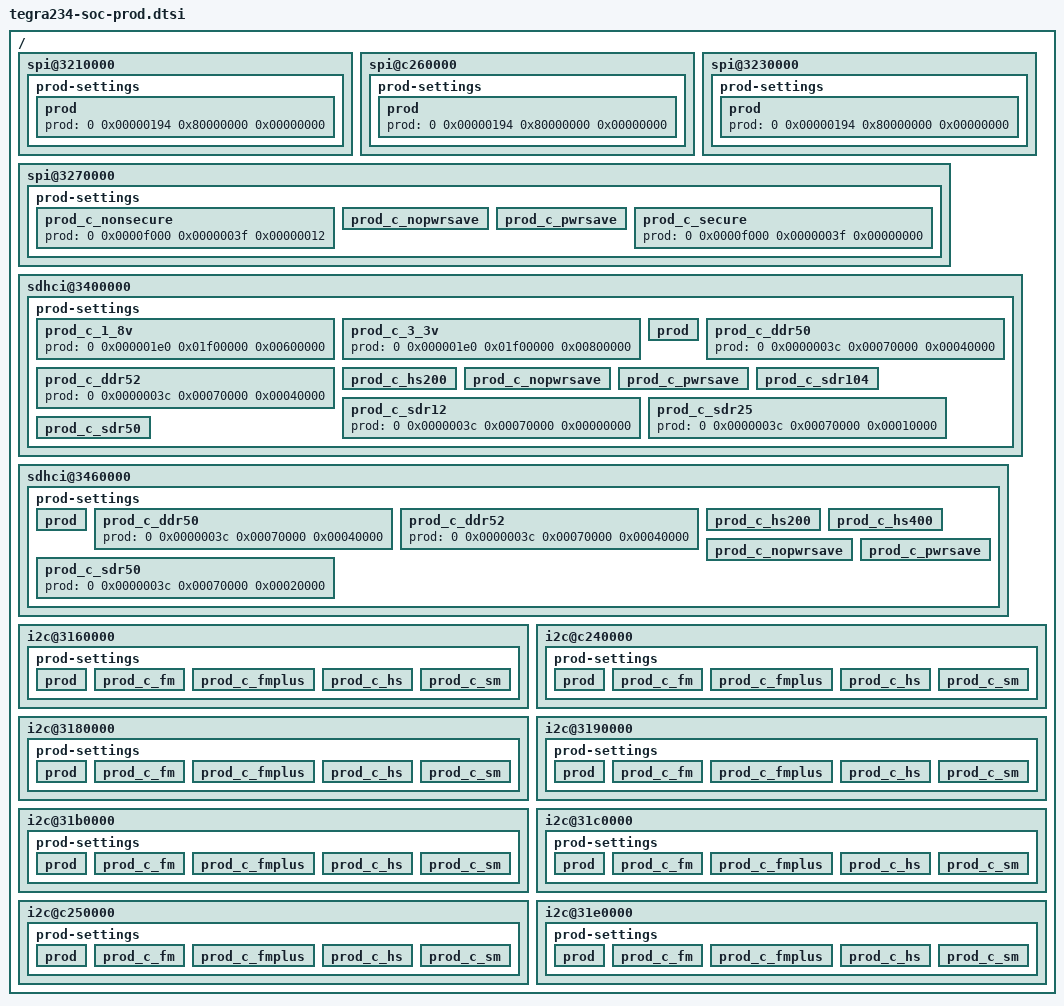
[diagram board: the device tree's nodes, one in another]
/*
 * Copyright (c) 2021, NVIDIA CORPORATION.  All rights reserved.
 *
 * This program is free software; you can redistribute it and/or modify it
 * under the terms and conditions of the GNU General Public License,
 * version 2, as published by the Free Software Foundation.
 *
 * This program is distributed in the hope it will be useful, but WITHOUT
 * ANY WARRANTY; without even the implied warranty of MERCHANTABILITY or
 * FITNESS FOR A PARTICULAR PURPOSE.  See the GNU General Public License for
 * more details.
 *
 * You should have received a copy of the GNU General Public License
 * along with this program.  If not, see <http://www.gnu.org/licenses/>.
 */

/*
* tegra234-soc-prod.dtsi: soc specific Prod configuration.
* Generation date: 2021-08-03 01:08
* PLEASE DO NOT EDIT THIS FILE MANUALLY
* This file is autogenerated using the script gen_prod_dtsi.py V2.3
*/

/ {
	spi@3210000 {
		prod-settings {
			#prod-cells = <4>;
			prod {
				prod = <
					0 0x00000194 0x80000000 0x00000000>;            //SPI_MISC_0
			};
		};
	};

	spi@c260000 {
		prod-settings {
			#prod-cells = <4>;
			prod {
				prod = <
					0 0x00000194 0x80000000 0x00000000>;            //SPI_MISC_0
			};
		};
	};

	spi@3230000 {
		prod-settings {
			#prod-cells = <4>;
			prod {
				prod = <
					0 0x00000194 0x80000000 0x00000000>;            //SPI_MISC_0
			};
		};
	};

	spi@3270000 {
		prod-settings {
			#prod-cells = <4>;
			prod_c_nonsecure {
				prod = <
					0 0x0000f000 0x0000003f 0x00000012>;            //QSPI_SECURE_AXI_CTL_0
			};
			prod_c_nopwrsave {
				prod = <
					0 0x00000194 0x80000000 0x80000000              //QSPI_MISC_0
					0 0x000001ec 0x00000002 0x00000000              //QSPI_QSPI_COMP_CONTROL_0
					0 0x000001fc 0x00000002 0x00000000>;            //QSPI_IO_TRIM_CNTRL_0
			};
			prod_c_pwrsave {
				prod = <
					0 0x00000194 0x80000000 0x00000000              //QSPI_MISC_0
					0 0x000001ec 0x00000002 0x00000002              //QSPI_QSPI_COMP_CONTROL_0
					0 0x000001fc 0x00000002 0x00000002>;            //QSPI_IO_TRIM_CNTRL_0
			};
			prod_c_secure {
				prod = <
					0 0x0000f000 0x0000003f 0x00000000>;            //QSPI_SECURE_AXI_CTL_0
			};
		};
	};

	sdhci@3400000 {
		prod-settings {
			#prod-cells = <4>;
			prod_c_1_8v {
				prod = <
					0 0x000001e0 0x01f00000 0x00600000>;            //SDMMCA_SDMEMCOMPPADCTRL_0
			};
			prod_c_3_3v {
				prod = <
					0 0x000001e0 0x01f00000 0x00800000>;            //SDMMCA_SDMEMCOMPPADCTRL_0
			};
			prod {
				prod = <
					0 0x00000028 0x00000022 0x00000002              //SDMMCA_POWER_CONTROL_HOST_0
					0 0x00000100 0x1fff006a 0x0e080020              //SDMMCA_VENDOR_CLOCK_CNTRL_0
					0 0x00000128 0x42000000 0x00000000              //SDMMCA_VENDOR_MISC_CNTRL2_0
					0 0x000001c0 0x00001fc0 0x00000040              //SDMMCA_VENDOR_TUNING_CNTRL0_0
					0 0x000001e0 0x0001f000 0x00007000              //SDMMCA_SDMEMCOMPPADCTRL_0
					0 0x000001e4 0x20000000 0x20000000>;            //SDMMCA_AUTO_CAL_CONFIG_0
			};
			prod_c_ddr50 {
				prod = <
					0 0x0000003c 0x00070000 0x00040000>;            //SDMMCA_AUTO_CMD12_ERR_STATUS_0
			};
			prod_c_ddr52 {
				prod = <
					0 0x0000003c 0x00070000 0x00040000>;            //SDMMCA_AUTO_CMD12_ERR_STATUS_0
			};
			prod_c_hs200 {
				prod = <
					0 0x0000003c 0x00070000 0x00030000              //SDMMCA_AUTO_CMD12_ERR_STATUS_0
					0 0x000001c0 0x0000e000 0x00004000>;            //SDMMCA_VENDOR_TUNING_CNTRL0_0
			};
			prod_c_nopwrsave {
				prod = <
					0 0x00000100 0x00000001 0x00000001              //SDMMCA_VENDOR_CLOCK_CNTRL_0
					0 0x000001ac 0x00000004 0x00000000>;            //SDMMCA_VENDOR_IO_TRIM_CNTRL_0
			};
			prod_c_pwrsave {
				prod = <
					0 0x00000100 0x00000001 0x00000000              //SDMMCA_VENDOR_CLOCK_CNTRL_0
					0 0x000001ac 0x00000004 0x00000004>;            //SDMMCA_VENDOR_IO_TRIM_CNTRL_0
			};
			prod_c_sdr104 {
				prod = <
					0 0x0000003c 0x00070000 0x00030000              //SDMMCA_AUTO_CMD12_ERR_STATUS_0
					0 0x000001c0 0x0000e000 0x00004000>;            //SDMMCA_VENDOR_TUNING_CNTRL0_0
			};
			prod_c_sdr12 {
				prod = <
					0 0x0000003c 0x00070000 0x00000000>;            //SDMMCA_AUTO_CMD12_ERR_STATUS_0
			};
			prod_c_sdr25 {
				prod = <
					0 0x0000003c 0x00070000 0x00010000>;            //SDMMCA_AUTO_CMD12_ERR_STATUS_0
			};
			prod_c_sdr50 {
				prod = <
					0 0x0000003c 0x00070000 0x00020000              //SDMMCA_AUTO_CMD12_ERR_STATUS_0
					0 0x000001c0 0x0000e000 0x00008000>;            //SDMMCA_VENDOR_TUNING_CNTRL0_0
			};
		};
	};

	sdhci@3460000 {
		prod-settings {
			#prod-cells = <4>;
			prod {
				prod = <
					0 0x00000004 0x00000fff 0x00000200              //SDMMCAB_BLOCK_SIZE_BLOCK_COUNT_0
					0 0x00000028 0x00000020 0x00000020              //SDMMCAB_POWER_CONTROL_HOST_0
					0 0x00000100 0x1fff006a 0x12070020              //SDMMCAB_VENDOR_CLOCK_CNTRL_0
					0 0x00000120 0x0000fffe 0x00000298              //SDMMCAB_VENDOR_MISC_CNTRL_0
					0 0x00000128 0x43000000 0x00000000              //SDMMCAB_VENDOR_MISC_CNTRL2_0
					0 0x000001c0 0x00001fc0 0x00000040              //SDMMCAB_VENDOR_TUNING_CNTRL0_0
					0 0x000001e0 0x01f1f000 0x00a0a000              //SDMMCAB_SDMEMCOMPPADCTRL_0
					0 0x000001e4 0x20000000 0x20000000>;            //SDMMCAB_AUTO_CAL_CONFIG_0
			};
			prod_c_ddr50 {
				prod = <
					0 0x0000003c 0x00070000 0x00040000>;            //SDMMCAB_AUTO_CMD12_ERR_STATUS_0
			};
			prod_c_ddr52 {
				prod = <
					0 0x0000003c 0x00070000 0x00040000>;            //SDMMCAB_AUTO_CMD12_ERR_STATUS_0
			};
			prod_c_hs200 {
				prod = <
					0 0x0000003c 0x00070000 0x00030000              //SDMMCAB_AUTO_CMD12_ERR_STATUS_0
					0 0x000001c0 0x0000e000 0x00004000>;            //SDMMCAB_VENDOR_TUNING_CNTRL0_0
			};
			prod_c_hs400 {
				prod = <
					0 0x0000003c 0x00070000 0x00050000              //SDMMCAB_AUTO_CMD12_ERR_STATUS_0
					0 0x00000100 0x00000008 0x00000008              //SDMMCAB_VENDOR_CLOCK_CNTRL_0
					0 0x0000010c 0x00003f00 0x00002800              //SDMMCAB_VENDOR_CAP_OVERRIDES_0
					0 0x000001c0 0x0000e000 0x00004000>;            //SDMMCAB_VENDOR_TUNING_CNTRL0_0
			};
			prod_c_nopwrsave {
				prod = <
					0 0x00000100 0x00000001 0x00000001              //SDMMCAB_VENDOR_CLOCK_CNTRL_0
					0 0x000001ac 0x00000004 0x00000000>;            //SDMMCAB_VENDOR_IO_TRIM_CNTRL_0
			};
			prod_c_pwrsave {
				prod = <
					0 0x00000100 0x00000001 0x00000000              //SDMMCAB_VENDOR_CLOCK_CNTRL_0
					0 0x000001ac 0x00000004 0x00000004>;            //SDMMCAB_VENDOR_IO_TRIM_CNTRL_0
			};
			prod_c_sdr50 {
				prod = <
					0 0x0000003c 0x00070000 0x00020000>;            //SDMMCAB_AUTO_CMD12_ERR_STATUS_0
			};
		};
	};
	i2c@3160000 {
		prod-settings {
			#prod-cells = <4>;
			prod {
				prod = <
					0 0x0000009c 0x0000ffff 0x00000308              //I2C_I2C_HS_INTERFACE_TIMING_0_0
					0 0x000000d4 0x000000ff 0x00000000              //I2C_I2C_INTERFACE_TIMING_2_0
					0 0x000000d8 0x000000ff 0x00000000              //I2C_I2C_HS_INTERFACE_TIMING_2_0
					0 0x000000dc 0x0000ffff 0x00000001              //I2C_I2C_MSTR_DATA_CAPTURE_TIMING_0
					0 0x000000e0 0x0000ffff 0x00000002>;            //I2C_I2C_SLV_DATA_CAPTURE_TIMING_0
			};
			prod_c_fm {
				prod = <
					0 0x0000006c 0xffff0000 0x00580000              //I2C_I2C_CLK_DIVISOR_REGISTER_0
					0 0x00000094 0x0000ffff 0x00000101              //I2C_I2C_INTERFACE_TIMING_0_0
					0 0x00000098 0xffffffff 0x02020202>;            //I2C_I2C_INTERFACE_TIMING_1_0
			};
			prod_c_fmplus {
				prod = <
					0 0x0000006c 0xffff0000 0x00240000              //I2C_I2C_CLK_DIVISOR_REGISTER_0
					0 0x00000094 0x0000ffff 0x00000101              //I2C_I2C_INTERFACE_TIMING_0_0
					0 0x00000098 0xffffffff 0x02020202>;            //I2C_I2C_INTERFACE_TIMING_1_0
			};
			prod_c_hs {
				prod = <
					0 0x0000006c 0xffffffff 0x00580002              //I2C_I2C_CLK_DIVISOR_REGISTER_0
					0 0x00000094 0x0000ffff 0x00000101              //I2C_I2C_INTERFACE_TIMING_0_0
					0 0x00000098 0xffffffff 0x02020202              //I2C_I2C_INTERFACE_TIMING_1_0
					0 0x000000a0 0x00ffffff 0x00090909>;            //I2C_I2C_HS_INTERFACE_TIMING_1_0
			};
			prod_c_sm {
				prod = <
					0 0x0000006c 0xffff0000 0x004f0000              //I2C_I2C_CLK_DIVISOR_REGISTER_0
					0 0x00000094 0x0000ffff 0x00000708              //I2C_I2C_INTERFACE_TIMING_0_0
					0 0x00000098 0xffffffff 0x08080808>;            //I2C_I2C_INTERFACE_TIMING_1_0
			};
		};
	};

	i2c@c240000 {
		prod-settings {
			#prod-cells = <4>;
			prod {
				prod = <
					0 0x0000009c 0x0000ffff 0x00000308              //I2C_I2C_HS_INTERFACE_TIMING_0_0
					0 0x000000d4 0x000000ff 0x00000000              //I2C_I2C_INTERFACE_TIMING_2_0
					0 0x000000d8 0x000000ff 0x00000000              //I2C_I2C_HS_INTERFACE_TIMING_2_0
					0 0x000000dc 0x0000ffff 0x00000001              //I2C_I2C_MSTR_DATA_CAPTURE_TIMING_0
					0 0x000000e0 0x0000ffff 0x00000002>;            //I2C_I2C_SLV_DATA_CAPTURE_TIMING_0
			};
			prod_c_fm {
				prod = <
					0 0x0000006c 0xffff0000 0x00580000              //I2C_I2C_CLK_DIVISOR_REGISTER_0
					0 0x00000094 0x0000ffff 0x00000101              //I2C_I2C_INTERFACE_TIMING_0_0
					0 0x00000098 0xffffffff 0x02020202>;            //I2C_I2C_INTERFACE_TIMING_1_0
			};
			prod_c_fmplus {
				prod = <
					0 0x0000006c 0xffff0000 0x00240000              //I2C_I2C_CLK_DIVISOR_REGISTER_0
					0 0x00000094 0x0000ffff 0x00000101              //I2C_I2C_INTERFACE_TIMING_0_0
					0 0x00000098 0xffffffff 0x02020202>;            //I2C_I2C_INTERFACE_TIMING_1_0
			};
			prod_c_hs {
				prod = <
					0 0x0000006c 0xffffffff 0x00580002              //I2C_I2C_CLK_DIVISOR_REGISTER_0
					0 0x00000094 0x0000ffff 0x00000101              //I2C_I2C_INTERFACE_TIMING_0_0
					0 0x00000098 0xffffffff 0x02020202              //I2C_I2C_INTERFACE_TIMING_1_0
					0 0x000000a0 0x00ffffff 0x00090909>;            //I2C_I2C_HS_INTERFACE_TIMING_1_0
			};
			prod_c_sm {
				prod = <
					0 0x0000006c 0xffff0000 0x004f0000              //I2C_I2C_CLK_DIVISOR_REGISTER_0
					0 0x00000094 0x0000ffff 0x00000708              //I2C_I2C_INTERFACE_TIMING_0_0
					0 0x00000098 0xffffffff 0x08080808>;            //I2C_I2C_INTERFACE_TIMING_1_0
			};
		};
	};

	i2c@3180000 {
		prod-settings {
			#prod-cells = <4>;
			prod {
				prod = <
					0 0x0000009c 0x0000ffff 0x00000308              //I2C_I2C_HS_INTERFACE_TIMING_0_0
					0 0x000000d4 0x000000ff 0x00000000              //I2C_I2C_INTERFACE_TIMING_2_0
					0 0x000000d8 0x000000ff 0x00000000              //I2C_I2C_HS_INTERFACE_TIMING_2_0
					0 0x000000dc 0x0000ffff 0x00000001              //I2C_I2C_MSTR_DATA_CAPTURE_TIMING_0
					0 0x000000e0 0x0000ffff 0x00000002>;            //I2C_I2C_SLV_DATA_CAPTURE_TIMING_0
			};
			prod_c_fm {
				prod = <
					0 0x0000006c 0xffff0000 0x00580000              //I2C_I2C_CLK_DIVISOR_REGISTER_0
					0 0x00000094 0x0000ffff 0x00000101              //I2C_I2C_INTERFACE_TIMING_0_0
					0 0x00000098 0xffffffff 0x02020202>;            //I2C_I2C_INTERFACE_TIMING_1_0
			};
			prod_c_fmplus {
				prod = <
					0 0x0000006c 0xffff0000 0x00240000              //I2C_I2C_CLK_DIVISOR_REGISTER_0
					0 0x00000094 0x0000ffff 0x00000101              //I2C_I2C_INTERFACE_TIMING_0_0
					0 0x00000098 0xffffffff 0x02020202>;            //I2C_I2C_INTERFACE_TIMING_1_0
			};
			prod_c_hs {
				prod = <
					0 0x0000006c 0xffffffff 0x00580002              //I2C_I2C_CLK_DIVISOR_REGISTER_0
					0 0x00000094 0x0000ffff 0x00000101              //I2C_I2C_INTERFACE_TIMING_0_0
					0 0x00000098 0xffffffff 0x02020202              //I2C_I2C_INTERFACE_TIMING_1_0
					0 0x000000a0 0x00ffffff 0x00090909>;            //I2C_I2C_HS_INTERFACE_TIMING_1_0
			};
			prod_c_sm {
				prod = <
					0 0x0000006c 0xffff0000 0x004f0000              //I2C_I2C_CLK_DIVISOR_REGISTER_0
					0 0x00000094 0x0000ffff 0x00000708              //I2C_I2C_INTERFACE_TIMING_0_0
					0 0x00000098 0xffffffff 0x08080808>;            //I2C_I2C_INTERFACE_TIMING_1_0
			};
		};
	};

	i2c@3190000 {
		prod-settings {
			#prod-cells = <4>;
			prod {
				prod = <
					0 0x0000009c 0x0000ffff 0x00000308              //I2C_I2C_HS_INTERFACE_TIMING_0_0
					0 0x000000d4 0x000000ff 0x00000000              //I2C_I2C_INTERFACE_TIMING_2_0
					0 0x000000d8 0x000000ff 0x00000000              //I2C_I2C_HS_INTERFACE_TIMING_2_0
					0 0x000000dc 0x0000ffff 0x00000001              //I2C_I2C_MSTR_DATA_CAPTURE_TIMING_0
					0 0x000000e0 0x0000ffff 0x00000002>;            //I2C_I2C_SLV_DATA_CAPTURE_TIMING_0
			};
			prod_c_fm {
				prod = <
					0 0x0000006c 0xffff0000 0x00580000              //I2C_I2C_CLK_DIVISOR_REGISTER_0
					0 0x00000094 0x0000ffff 0x00000101              //I2C_I2C_INTERFACE_TIMING_0_0
					0 0x00000098 0xffffffff 0x02020202>;            //I2C_I2C_INTERFACE_TIMING_1_0
			};
			prod_c_fmplus {
				prod = <
					0 0x0000006c 0xffff0000 0x00240000              //I2C_I2C_CLK_DIVISOR_REGISTER_0
					0 0x00000094 0x0000ffff 0x00000101              //I2C_I2C_INTERFACE_TIMING_0_0
					0 0x00000098 0xffffffff 0x02020202>;            //I2C_I2C_INTERFACE_TIMING_1_0
			};
			prod_c_hs {
				prod = <
					0 0x0000006c 0xffffffff 0x00580002              //I2C_I2C_CLK_DIVISOR_REGISTER_0
					0 0x00000094 0x0000ffff 0x00000101              //I2C_I2C_INTERFACE_TIMING_0_0
					0 0x00000098 0xffffffff 0x02020202              //I2C_I2C_INTERFACE_TIMING_1_0
					0 0x000000a0 0x00ffffff 0x00090909>;            //I2C_I2C_HS_INTERFACE_TIMING_1_0
			};
			prod_c_sm {
				prod = <
					0 0x0000006c 0xffff0000 0x004f0000              //I2C_I2C_CLK_DIVISOR_REGISTER_0
					0 0x00000094 0x0000ffff 0x00000708              //I2C_I2C_INTERFACE_TIMING_0_0
					0 0x00000098 0xffffffff 0x08080808>;            //I2C_I2C_INTERFACE_TIMING_1_0
			};
		};
	};
        i2c@31b0000 {
		prod-settings {
			#prod-cells = <4>;
			prod {
				prod = <
					0 0x0000009c 0x0000ffff 0x00000308              //I2C_I2C_HS_INTERFACE_TIMING_0_0
					0 0x000000d4 0x000000ff 0x00000000              //I2C_I2C_INTERFACE_TIMING_2_0
					0 0x000000d8 0x000000ff 0x00000000              //I2C_I2C_HS_INTERFACE_TIMING_2_0
					0 0x000000dc 0x0000ffff 0x00000001              //I2C_I2C_MSTR_DATA_CAPTURE_TIMING_0
					0 0x000000e0 0x0000ffff 0x00000002>;            //I2C_I2C_SLV_DATA_CAPTURE_TIMING_0
			};
			prod_c_fm {
				prod = <
					0 0x0000006c 0xffff0000 0x00580000              //I2C_I2C_CLK_DIVISOR_REGISTER_0
					0 0x00000094 0x0000ffff 0x00000101              //I2C_I2C_INTERFACE_TIMING_0_0
					0 0x00000098 0xffffffff 0x02020202>;            //I2C_I2C_INTERFACE_TIMING_1_0
			};
			prod_c_fmplus {
				prod = <
					0 0x0000006c 0xffff0000 0x00240000              //I2C_I2C_CLK_DIVISOR_REGISTER_0
					0 0x00000094 0x0000ffff 0x00000101              //I2C_I2C_INTERFACE_TIMING_0_0
					0 0x00000098 0xffffffff 0x02020202>;            //I2C_I2C_INTERFACE_TIMING_1_0
			};
			prod_c_hs {
				prod = <
					0 0x0000006c 0xffffffff 0x00580002              //I2C_I2C_CLK_DIVISOR_REGISTER_0
					0 0x00000094 0x0000ffff 0x00000101              //I2C_I2C_INTERFACE_TIMING_0_0
					0 0x00000098 0xffffffff 0x02020202              //I2C_I2C_INTERFACE_TIMING_1_0
					0 0x000000a0 0x00ffffff 0x00090909>;            //I2C_I2C_HS_INTERFACE_TIMING_1_0
			};
			prod_c_sm {
				prod = <
					0 0x0000006c 0xffff0000 0x004f0000              //I2C_I2C_CLK_DIVISOR_REGISTER_0
					0 0x00000094 0x0000ffff 0x00000708              //I2C_I2C_INTERFACE_TIMING_0_0
					0 0x00000098 0xffffffff 0x08080808>;            //I2C_I2C_INTERFACE_TIMING_1_0
			};
		};
	};

	i2c@31c0000 {
		prod-settings {
			#prod-cells = <4>;
			prod {
				prod = <
					0 0x0000009c 0x0000ffff 0x00000308              //I2C_I2C_HS_INTERFACE_TIMING_0_0
					0 0x000000d4 0x000000ff 0x00000000              //I2C_I2C_INTERFACE_TIMING_2_0
					0 0x000000d8 0x000000ff 0x00000000              //I2C_I2C_HS_INTERFACE_TIMING_2_0
					0 0x000000dc 0x0000ffff 0x00000001              //I2C_I2C_MSTR_DATA_CAPTURE_TIMING_0
					0 0x000000e0 0x0000ffff 0x00000002>;            //I2C_I2C_SLV_DATA_CAPTURE_TIMING_0
			};
			prod_c_fm {
				prod = <
					0 0x0000006c 0xffff0000 0x00580000              //I2C_I2C_CLK_DIVISOR_REGISTER_0
					0 0x00000094 0x0000ffff 0x00000101              //I2C_I2C_INTERFACE_TIMING_0_0
					0 0x00000098 0xffffffff 0x02020202>;            //I2C_I2C_INTERFACE_TIMING_1_0
			};
			prod_c_fmplus {
				prod = <
					0 0x0000006c 0xffff0000 0x00240000              //I2C_I2C_CLK_DIVISOR_REGISTER_0
					0 0x00000094 0x0000ffff 0x00000101              //I2C_I2C_INTERFACE_TIMING_0_0
					0 0x00000098 0xffffffff 0x02020202>;            //I2C_I2C_INTERFACE_TIMING_1_0
			};
			prod_c_hs {
				prod = <
					0 0x0000006c 0xffffffff 0x00580002              //I2C_I2C_CLK_DIVISOR_REGISTER_0
					0 0x00000094 0x0000ffff 0x00000101              //I2C_I2C_INTERFACE_TIMING_0_0
					0 0x00000098 0xffffffff 0x02020202              //I2C_I2C_INTERFACE_TIMING_1_0
					0 0x000000a0 0x00ffffff 0x00090909>;            //I2C_I2C_HS_INTERFACE_TIMING_1_0
			};
			prod_c_sm {
				prod = <
					0 0x0000006c 0xffff0000 0x004f0000              //I2C_I2C_CLK_DIVISOR_REGISTER_0
					0 0x00000094 0x0000ffff 0x00000708              //I2C_I2C_INTERFACE_TIMING_0_0
					0 0x00000098 0xffffffff 0x08080808>;            //I2C_I2C_INTERFACE_TIMING_1_0
			};
		};
	};

	i2c@c250000 {
		prod-settings {
			#prod-cells = <4>;
			prod {
				prod = <
					0 0x0000009c 0x0000ffff 0x00000308              //I2C_I2C_HS_INTERFACE_TIMING_0_0
					0 0x000000d4 0x000000ff 0x00000000              //I2C_I2C_INTERFACE_TIMING_2_0
					0 0x000000d8 0x000000ff 0x00000000              //I2C_I2C_HS_INTERFACE_TIMING_2_0
					0 0x000000dc 0x0000ffff 0x00000001              //I2C_I2C_MSTR_DATA_CAPTURE_TIMING_0
					0 0x000000e0 0x0000ffff 0x00000002>;            //I2C_I2C_SLV_DATA_CAPTURE_TIMING_0
			};
			prod_c_fm {
				prod = <
					0 0x0000006c 0xffff0000 0x00580000              //I2C_I2C_CLK_DIVISOR_REGISTER_0
					0 0x00000094 0x0000ffff 0x00000101              //I2C_I2C_INTERFACE_TIMING_0_0
					0 0x00000098 0xffffffff 0x02020202>;            //I2C_I2C_INTERFACE_TIMING_1_0
			};
			prod_c_fmplus {
				prod = <
					0 0x0000006c 0xffff0000 0x00240000              //I2C_I2C_CLK_DIVISOR_REGISTER_0
					0 0x00000094 0x0000ffff 0x00000101              //I2C_I2C_INTERFACE_TIMING_0_0
					0 0x00000098 0xffffffff 0x02020202>;            //I2C_I2C_INTERFACE_TIMING_1_0
			};
			prod_c_hs {
				prod = <
					0 0x0000006c 0xffffffff 0x00580002              //I2C_I2C_CLK_DIVISOR_REGISTER_0
					0 0x00000094 0x0000ffff 0x00000101              //I2C_I2C_INTERFACE_TIMING_0_0
					0 0x00000098 0xffffffff 0x02020202              //I2C_I2C_INTERFACE_TIMING_1_0
					0 0x000000a0 0x00ffffff 0x00090909>;            //I2C_I2C_HS_INTERFACE_TIMING_1_0
			};
			prod_c_sm {
				prod = <
					0 0x0000006c 0xffff0000 0x004f0000              //I2C_I2C_CLK_DIVISOR_REGISTER_0
					0 0x00000094 0x0000ffff 0x00000708              //I2C_I2C_INTERFACE_TIMING_0_0
					0 0x00000098 0xffffffff 0x08080808>;            //I2C_I2C_INTERFACE_TIMING_1_0
			};
		};
	};

	i2c@31e0000 {
		prod-settings {
			#prod-cells = <4>;
			prod {
				prod = <
					0 0x0000009c 0x0000ffff 0x00000308              //I2C_I2C_HS_INTERFACE_TIMING_0_0
					0 0x000000d4 0x000000ff 0x00000000              //I2C_I2C_INTERFACE_TIMING_2_0
					0 0x000000d8 0x000000ff 0x00000000              //I2C_I2C_HS_INTERFACE_TIMING_2_0
					0 0x000000dc 0x0000ffff 0x00000001              //I2C_I2C_MSTR_DATA_CAPTURE_TIMING_0
					0 0x000000e0 0x0000ffff 0x00000002>;            //I2C_I2C_SLV_DATA_CAPTURE_TIMING_0
			};
			prod_c_fm {
				prod = <
					0 0x0000006c 0xffff0000 0x00580000              //I2C_I2C_CLK_DIVISOR_REGISTER_0
					0 0x00000094 0x0000ffff 0x00000101              //I2C_I2C_INTERFACE_TIMING_0_0
					0 0x00000098 0xffffffff 0x02020202>;            //I2C_I2C_INTERFACE_TIMING_1_0
			};
			prod_c_fmplus {
				prod = <
					0 0x0000006c 0xffff0000 0x00240000              //I2C_I2C_CLK_DIVISOR_REGISTER_0
					0 0x00000094 0x0000ffff 0x00000101              //I2C_I2C_INTERFACE_TIMING_0_0
					0 0x00000098 0xffffffff 0x02020202>;            //I2C_I2C_INTERFACE_TIMING_1_0
			};
			prod_c_hs {
				prod = <
					0 0x0000006c 0xffffffff 0x00580002              //I2C_I2C_CLK_DIVISOR_REGISTER_0
					0 0x00000094 0x0000ffff 0x00000101              //I2C_I2C_INTERFACE_TIMING_0_0
					0 0x00000098 0xffffffff 0x02020202              //I2C_I2C_INTERFACE_TIMING_1_0
					0 0x000000a0 0x00ffffff 0x00090909>;            //I2C_I2C_HS_INTERFACE_TIMING_1_0
			};
			prod_c_sm {
				prod = <
					0 0x0000006c 0xffff0000 0x004f0000              //I2C_I2C_CLK_DIVISOR_REGISTER_0
					0 0x00000094 0x0000ffff 0x00000708              //I2C_I2C_INTERFACE_TIMING_0_0
					0 0x00000098 0xffffffff 0x08080808>;            //I2C_I2C_INTERFACE_TIMING_1_0
			};
		};
	};

	
};
